# R7FA8M1AH register map
Vendor: Renesas; Series: RA8; File version: 1.2
CPU: CM85 r0p0, little endian, MPU, FPU, VTOR, 4 interrupt priority bits
Registers are 32-bit, read-write, reset 0x0 unless marked. A register's access mark holds for its fields unless they carry their own. Offsets are from the block's base; [hi:lo] are bit positions; {n}, {i} and the like mark numbered series; 'fields as' and 'values as' point back to an identical list.

## I3C (part 4 of 4) — I2C I3C unified IP
Base 0x4035F000
Same registers: I3C_NS 0x5035F000
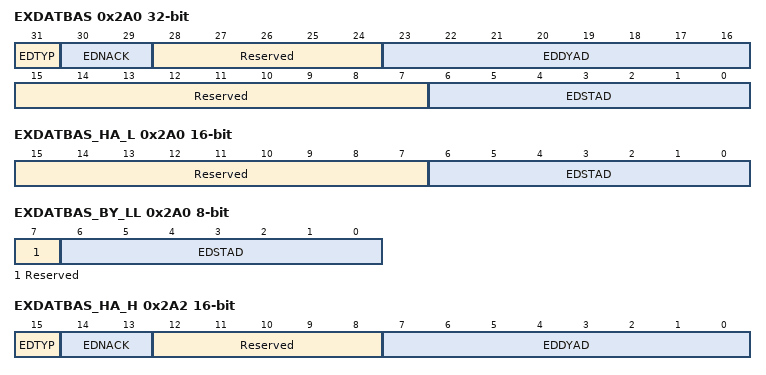
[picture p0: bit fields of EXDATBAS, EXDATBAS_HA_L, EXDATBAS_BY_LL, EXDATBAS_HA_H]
0x2A0 EXDATBAS — Extended Device Address Table Basic Register
  [31] EDTYP — Extended Device Type
    0=I3C: I3C Device; 1=I2C: I2C Device
  [30:29] EDNACK — Extended Device NACK Retry Count
  [28:24] Reserved — These bits are read as 00000. The write value should be 00000.
  [23:16] EDDYAD — Extended Device I3C Dynamic Address
  [15:7] Reserved — These bits are read as 000000000. The write value should be 000000000.
  [6:0] EDSTAD — Extended Device Static Address
0x2A0 EXDATBAS_HA_L 16-bit — Extended Device Address Table Basic Register
  [15:7] Reserved — These bits are read as 000000000. The write value should be 000000000.
  [6:0] EDSTAD — Extended Device Static Address
0x2A0 EXDATBAS_BY_LL 8-bit — Extended Device Address Table Basic Register
  [7] Reserved — This bit is read as 0. The write value should be 0.
  [6:0] EDSTAD — Extended Device Static Address
0x2A1 EXDATBAS_BY_LH 8-bit — Extended Device Address Table Basic Register
  [7:0] Reserved — These bits are read as 00000000. The write value should be 00000000.
0x2A2 EXDATBAS_HA_H 16-bit — Extended Device Address Table Basic Register
  [15] EDTYP — Extended Device Type
    0=I3C: I3C Device; 1=I2C: I2C Device
  [14:13] EDNACK — Extended Device NACK Retry Count
  [12:8] Reserved — These bits are read as 00000. The write value should be 00000.
  [7:0] EDDYAD — Extended Device I3C Dynamic Address
0x2A2 EXDATBAS_BY_HL 8-bit — Extended Device Address Table Basic Register
  [7:0] EDDYAD — Extended Device I3C Dynamic Address
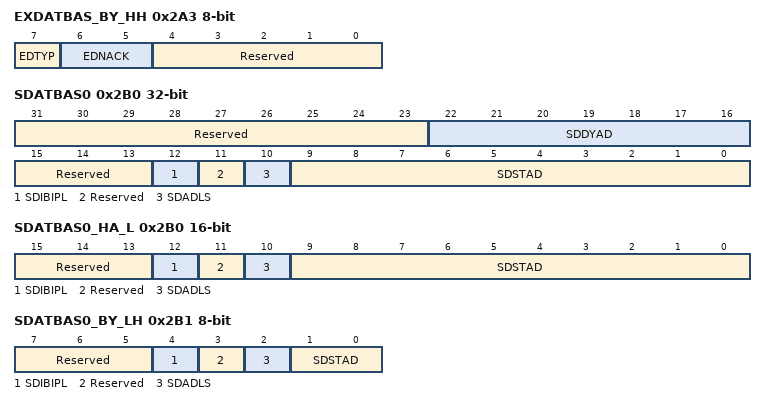
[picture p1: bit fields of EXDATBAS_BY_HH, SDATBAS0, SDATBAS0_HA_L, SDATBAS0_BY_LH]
0x2A3 EXDATBAS_BY_HH 8-bit — Extended Device Address Table Basic Register
  [7] EDTYP — Extended Device Type
    0=I3C: I3C Device; 1=I2C: I2C Device
  [6:5] EDNACK — Extended Device NACK Retry Count
  [4:0] Reserved — These bits are read as 00000. The write value should be 00000.
0x2B0 SDATBAS0 — Slave Device Address Table Basic Register 0
  [31:23] Reserved — These bits are read as 000000000. The write value should be 000000000.
  [22:16] SDDYAD read-modifies — Slave Device I3C Dynamic Address
  [15:13] Reserved — These bits are read as 000. The write value should be 000.
  [12] SDIBIPL ro — Slave Device IBI Payload
    0=IBIs from this Device do not carry a Data Payload; 1=IBIs from this Device do carry a Data Payload
  [11] Reserved — This bit is read as 0. The write value should be 0.
  [10] SDADLS — Slave Device Address Length Selection
    0=Slave Device address length 7 bits selected; 1=Slave Device address length 10 bits selected. (I2C device only)
  [9:0] SDSTAD — Slave Device Static Address
0x2B0 SDATBAS0_HA_L 16-bit — Slave Device Address Table Basic Register 0
  [15:13] Reserved — These bits are read as 000. The write value should be 000.
  [12] SDIBIPL ro — Slave Device IBI Payload
    values as SDATBAS0.SDIBIPL
  [11] Reserved — This bit is read as 0. The write value should be 0.
  [10] SDADLS — Slave Device Address Length Selection
    values as SDATBAS0.SDADLS
  [9:0] SDSTAD — Slave Device Static Address
{0x2B0+4i} SDATBAS{i}_BY_LL 8-bit (i=0..2) — Slave Device Address Table Basic Register {i}
  [7:0] SDSTAD — Slave Device Static Address
0x2B1 SDATBAS0_BY_LH 8-bit — Slave Device Address Table Basic Register 0
  [7:5] Reserved — These bits are read as 000. The write value should be 000.
  [4] SDIBIPL ro — Slave Device IBI Payload
    values as SDATBAS0.SDIBIPL
  [3] Reserved — This bit is read as 0. The write value should be 0.
  [2] SDADLS — Slave Device Address Length Selection
    values as SDATBAS0.SDADLS
  [1:0] SDSTAD — Slave Device Static Address
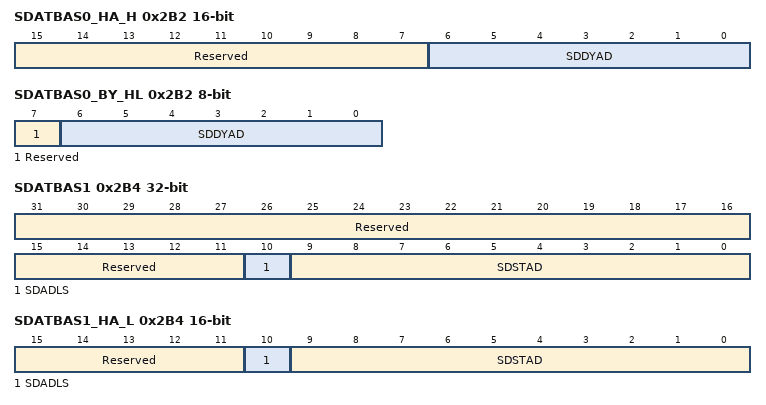
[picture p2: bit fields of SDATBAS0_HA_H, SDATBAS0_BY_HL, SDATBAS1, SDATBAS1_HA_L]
0x2B2 SDATBAS0_HA_H 16-bit — Slave Device Address Table Basic Register 0
  [15:7] Reserved — These bits are read as 000000000. The write value should be 000000000.
  [6:0] SDDYAD read-modifies — Slave Device I3C Dynamic Address
0x2B2 SDATBAS0_BY_HL 8-bit — Slave Device Address Table Basic Register 0
  [7] Reserved — This bit is read as 0. The write value should be 0.
  [6:0] SDDYAD read-modifies — Slave Device I3C Dynamic Address
0x2B4 SDATBAS1 — Slave Device Address Table Basic Register 1
  [31:11] Reserved — These bits are read as 000000000000000000000. The write value should be 000000000000000000000.
  [10] SDADLS — Slave Device Address Length Selection
    values as SDATBAS0.SDADLS
  [9:0] SDSTAD — Slave Device Static Address
0x2B4 SDATBAS1_HA_L 16-bit — Slave Device Address Table Basic Register 1
  [15:11] Reserved — These bits are read as 00000. The write value should be 00000.
  [10] SDADLS — Slave Device Address Length Selection
    values as SDATBAS0.SDADLS
  [9:0] SDSTAD — Slave Device Static Address
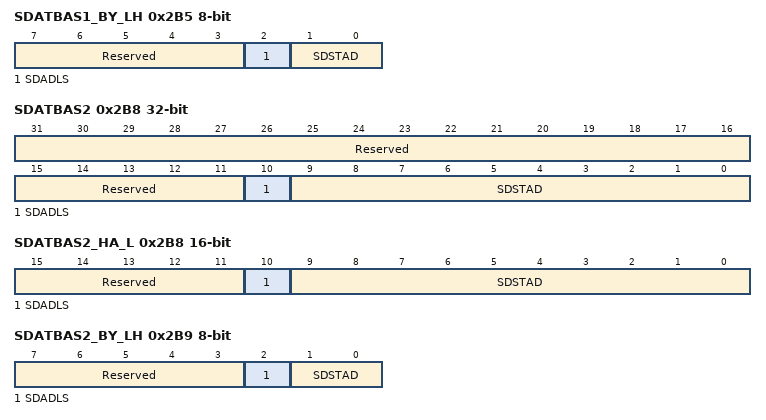
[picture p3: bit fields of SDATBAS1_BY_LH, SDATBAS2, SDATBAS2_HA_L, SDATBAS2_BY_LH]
0x2B5 SDATBAS1_BY_LH 8-bit — Slave Device Address Table Basic Register 1
  [7:3] Reserved — These bits are read as 00000. The write value should be 00000.
  [2] SDADLS — Slave Device Address Length Selection
    values as SDATBAS0.SDADLS
  [1:0] SDSTAD — Slave Device Static Address
0x2B8 SDATBAS2 — Slave Device Address Table Basic Register 2
  fields as SDATBAS1
0x2B8 SDATBAS2_HA_L 16-bit — Slave Device Address Table Basic Register 2
  fields as SDATBAS1_HA_L
0x2B9 SDATBAS2_BY_LH 8-bit — Slave Device Address Table Basic Register 2
  fields as SDATBAS1_BY_LH
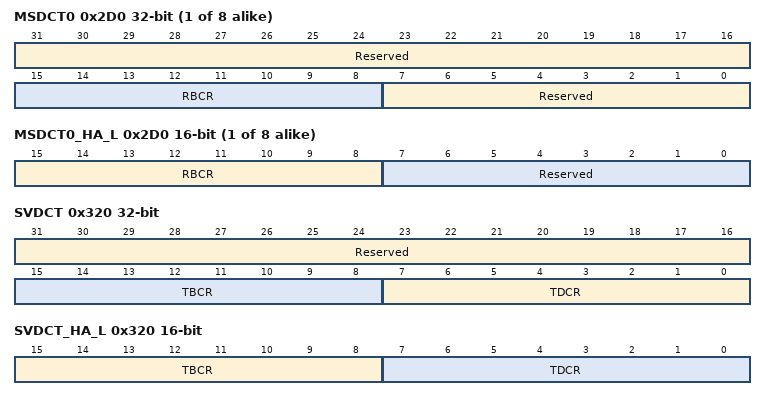
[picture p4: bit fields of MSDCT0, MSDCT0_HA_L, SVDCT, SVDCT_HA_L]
{0x2D0+4i} MSDCT{i} read-modifies (i=0..7) — Master Device Characteristic Table Register {i}
  [31:16] Reserved — These bits are read as 0000000000000000. The write value should be 0000000000000000.
  [15:8] RBCR read-modifies — Received Bus Characteristic RegisterValue of Device's I3C Bus Characteristics Register.
    0=– SDR only; 1=– HDR Capable; 0=– Not a Bridge Device; 1=– Is a Bridge Device; 0=– Device will always respond to I3C Bus commands; 1=– Device will not always respond to I3C Bus commands; 0=– No data byte follows the accepted IBI; 1=– Mandatory one or more data bytes follow the accepted IBI; 0=– Not Capable; 1=– Capable; 0=– No Limitation; 1=– Limitation
  [7:0] Reserved — These bits are read as 00000000. The write value should be 00000000.
{0x2D0+4i} MSDCT{i}_HA_L 16-bit read-modifies (i=0..7) — Master Device Characteristic Table Register {i}
  [15:8] RBCR read-modifies — Received Bus Characteristic RegisterValue of Device's I3C Bus Characteristics Register.
    values as MSDCT0.RBCR
  [7:0] Reserved — These bits are read as 00000000. The write value should be 00000000.
{0x2D1+4i} MSDCT{i}_BY_LH 8-bit read-modifies (i=0..7) — Master Device Characteristic Table Register {i}
  [7:0] RBCR read-modifies — Received Bus Characteristic RegisterValue of Device's I3C Bus Characteristics Register.
    values as MSDCT0.RBCR
0x320 SVDCT — Slave Device Characteristic Table Register
  [31:16] Reserved — These bits are read as 0000000000000000. The write value should be 0000000000000000.
  [15:8] TBCR — Transfar Bus Characteristic RegisterValue of Device's I3C Bus Characteristics Register.
    values as MSDCT0.RBCR
  [7:0] TDCR — Transfar Device Characteristic Register
0x320 SVDCT_HA_L 16-bit — Slave Device Characteristic Table Register
  [15:8] TBCR — Transfar Bus Characteristic RegisterValue of Device's I3C Bus Characteristics Register.
    values as MSDCT0.RBCR
  [7:0] TDCR — Transfar Device Characteristic Register
0x320 SVDCT_BY_LL 8-bit — Slave Device Characteristic Table Register
  [7:0] TDCR — Transfar Device Characteristic Register
0x321 SVDCT_BY_LH 8-bit — Slave Device Characteristic Table Register
  [7:0] TBCR — Transfar Bus Characteristic RegisterValue of Device's I3C Bus Characteristics Register.
    values as MSDCT0.RBCR
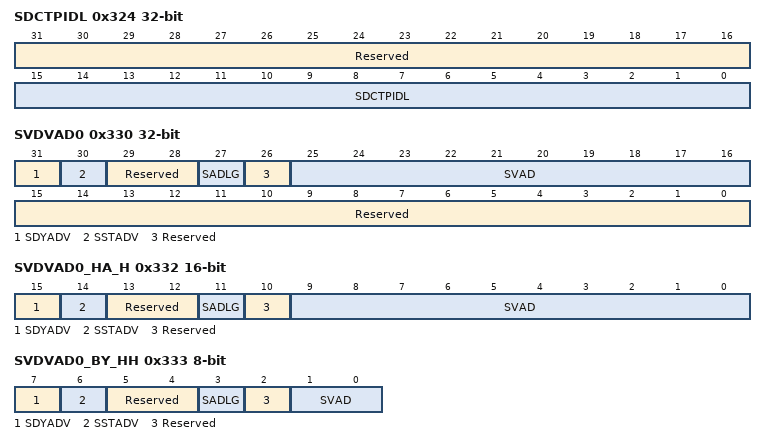
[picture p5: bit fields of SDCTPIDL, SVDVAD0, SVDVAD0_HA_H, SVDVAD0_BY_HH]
0x324 SDCTPIDL — Slave Device Characteristic Table Provisional ID Low Register
  [31:16] Reserved — These bits are read as 0000000000000000. The write value should be 0000000000000000.
  [15:0] SDCTPIDL — Transfar Device Provisional ID Low
0x324 SDCTPIDL_HA_L 16-bit — Slave Device Characteristic Table Provisional ID Low Register
  [15:0] SDCTPIDL — Transfar Device Provisional ID Low
0x324 SDCTPIDL_BY_LL 8-bit — Slave Device Characteristic Table Provisional ID Low Register
  [7:0] SDCTPIDL — Transfar Device Provisional ID Low
0x325 SDCTPIDL_BY_LH 8-bit — Slave Device Characteristic Table Provisional ID Low Register
  [7:0] SDCTPIDL — Transfar Device Provisional ID Low
0x328 SDCTPIDH — Slave Device Characteristic Table Provisional ID High Register
  [31:0] SDCTPIDH — Transfar Device Provisional ID High
0x328 SDCTPIDH_HA_L 16-bit — Slave Device Characteristic Table Provisional ID High Register
  [15:0] SDCTPIDH — Transfar Device Provisional ID High
0x328 SDCTPIDH_BY_LL 8-bit — Slave Device Characteristic Table Provisional ID High Register
  [7:0] SDCTPIDH — Transfar Device Provisional ID High
0x329 SDCTPIDH_BY_LH 8-bit — Slave Device Characteristic Table Provisional ID High Register
  [7:0] SDCTPIDH — Transfar Device Provisional ID High
0x32A SDCTPIDH_HA_H 16-bit — Slave Device Characteristic Table Provisional ID High Register
  [15:0] SDCTPIDH — Transfar Device Provisional ID High
0x32A SDCTPIDH_BY_HL 8-bit — Slave Device Characteristic Table Provisional ID High Register
  [7:0] SDCTPIDH — Transfar Device Provisional ID High
0x32B SDCTPIDH_BY_HH 8-bit — Slave Device Characteristic Table Provisional ID High Register
  [7:0] SDCTPIDH — Transfar Device Provisional ID High
0x330 SVDVAD0 ro — Slave Device Address Register 0
  [31] SDYADV — Slave Dynamic Address Valid
    0=Dynamic Address is disabled; 1=Dynamic Address is enabled
  [30] SSTADV — Slave Static Address Valid
    0=Slave address is disabled; 1=Slave address is enabled
  [29:28] Reserved — These bits are read as 00.
  [27] SADLG — Slave Address Length
    0=The 7-bit address format is selected; 1=The 10-bit address format is selected
  [26] Reserved — This bit is read as 0.
  [25:16] SVAD — Slave Address
  [15:0] Reserved — These bits are read as 0000000000000000.
0x332 SVDVAD0_HA_H 16-bit ro — Slave Device Address Register 0
  [15] SDYADV — Slave Dynamic Address Valid
    0=Dynamic Address is disabled; 1=Dynamic Address is enabled
  [14] SSTADV — Slave Static Address Valid
    0=Slave address is disabled; 1=Slave address is enabled
  [13:12] Reserved — These bits are read as 00.
  [11] SADLG — Slave Address Length
    values as SVDVAD0.SADLG
  [10] Reserved — This bit is read as 0.
  [9:0] SVAD — Slave Address
{0x332+4i} SVDVAD{i}_BY_HL 8-bit ro (i=0..2) — Slave Device Address Register {i}
  [7:0] SVAD — Slave Address
0x333 SVDVAD0_BY_HH 8-bit ro — Slave Device Address Register 0
  [7] SDYADV — Slave Dynamic Address Valid
    0=Dynamic Address is disabled; 1=Dynamic Address is enabled
  [6] SSTADV — Slave Static Address Valid
    0=Slave address is disabled; 1=Slave address is enabled
  [5:4] Reserved — These bits are read as 00.
  [3] SADLG — Slave Address Length
    values as SVDVAD0.SADLG
  [2] Reserved — This bit is read as 0.
  [1:0] SVAD — Slave Address
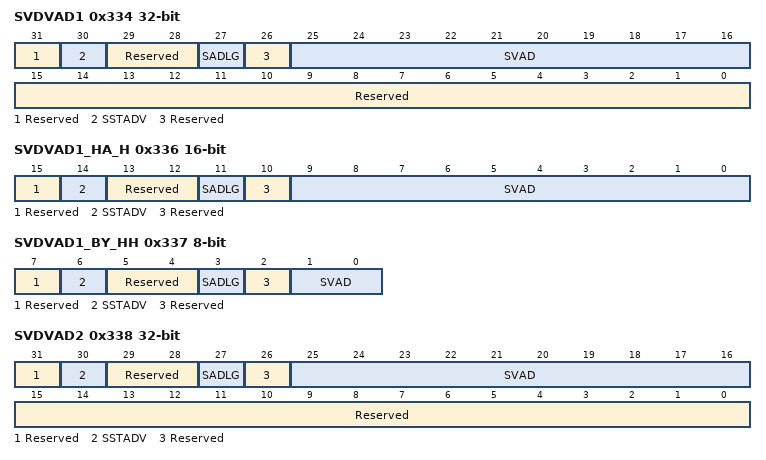
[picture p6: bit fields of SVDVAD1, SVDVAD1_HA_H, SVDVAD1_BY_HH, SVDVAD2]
0x334 SVDVAD1 ro — Slave Device Address Register 1
  [31] Reserved — This bit is read as 0.
  [30] SSTADV — Slave Static Address Valid
    0=Slave address is disabled; 1=Slave address is enabled
  [29:28] Reserved — These bits are read as 00.
  [27] SADLG — Slave Address Length
    values as SVDVAD0.SADLG
  [26] Reserved — This bit is read as 0.
  [25:16] SVAD — Slave Address
  [15:0] Reserved — These bits are read as 0000000000000000.
0x336 SVDVAD1_HA_H 16-bit ro — Slave Device Address Register 1
  [15] Reserved — This bit is read as 0.
  [14] SSTADV — Slave Static Address Valid
    0=Slave address is disabled; 1=Slave address is enabled
  [13:12] Reserved — These bits are read as 00.
  [11] SADLG — Slave Address Length
    values as SVDVAD0.SADLG
  [10] Reserved — This bit is read as 0.
  [9:0] SVAD — Slave Address
0x337 SVDVAD1_BY_HH 8-bit ro — Slave Device Address Register 1
  [7] Reserved — This bit is read as 0.
  [6] SSTADV — Slave Static Address Valid
    0=Slave address is disabled; 1=Slave address is enabled
  [5:4] Reserved — These bits are read as 00.
  [3] SADLG — Slave Address Length
    values as SVDVAD0.SADLG
  [2] Reserved — This bit is read as 0.
  [1:0] SVAD — Slave Address
0x338 SVDVAD2 ro — Slave Device Address Register 2
  fields as SVDVAD1
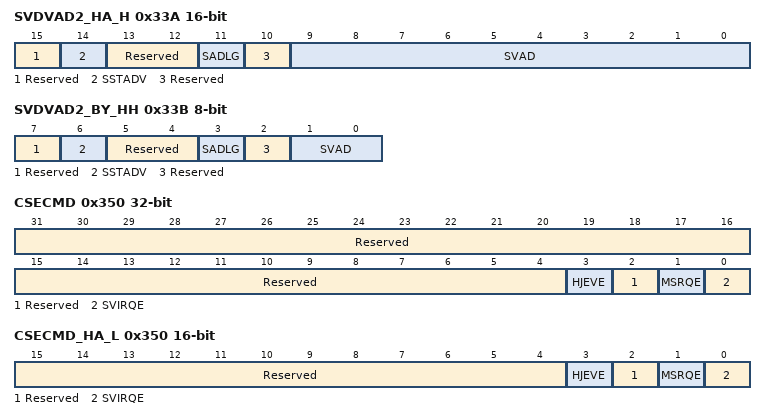
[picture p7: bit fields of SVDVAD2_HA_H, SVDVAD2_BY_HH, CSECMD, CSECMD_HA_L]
0x33A SVDVAD2_HA_H 16-bit ro — Slave Device Address Register 2
  fields as SVDVAD1_HA_H
0x33B SVDVAD2_BY_HH 8-bit ro — Slave Device Address Register 2
  fields as SVDVAD1_BY_HH
0x350 CSECMD read-modifies — CCC Slave Events Command Register
  [31:4] Reserved — These bits are read as 0000000000000000000000000000. The write value should be 0000000000000000000000000000.
  [3] HJEVE read-modifies — Hot-Join Event Enable
    0=DISABLED: Slave-initiated Hot-Join is Disabled by the Master to control; 1=ENABLED: Slave-initiated Hot-Join is Enabled by the Master to control
  [2] Reserved — This bit is read as 0. The write value should be 0.
  [1] MSRQE read-modifies — Mastership Requests Enable
    0=DISABLED: Mastership requests from Secondary Masters is Disabled by the Current Master to control; 1=ENABLED: Mastership requests from Secondary Masters is Enabled by the Current Master to control
  [0] SVIRQE read-modifies — Slave Interrupt Requests Enable
    0=DISABLED: Slave-initiated Interrupts is Disabled by the Master to control; 1=ENABLED: Slave-initiated Interrupts is Enabled by the Master to control
0x350 CSECMD_HA_L 16-bit read-modifies — CCC Slave Events Command Register
  [15:4] Reserved — These bits are read as 000000000000. The write value should be 000000000000.
  [3] HJEVE read-modifies — Hot-Join Event Enable
    values as CSECMD.HJEVE
  [2] Reserved — This bit is read as 0. The write value should be 0.
  [1] MSRQE read-modifies — Mastership Requests Enable
    values as CSECMD.MSRQE
  [0] SVIRQE read-modifies — Slave Interrupt Requests Enable
    values as CSECMD.SVIRQE
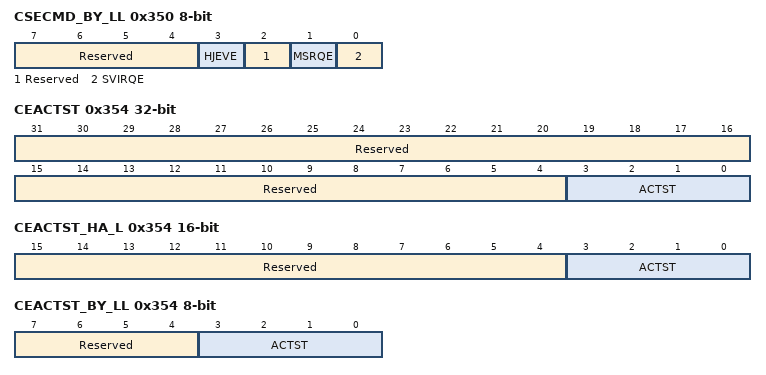
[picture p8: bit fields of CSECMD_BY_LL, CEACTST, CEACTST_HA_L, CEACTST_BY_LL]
0x350 CSECMD_BY_LL 8-bit read-modifies — CCC Slave Events Command Register
  [7:4] Reserved — These bits are read as 0000. The write value should be 0000.
  [3] HJEVE read-modifies — Hot-Join Event Enable
    values as CSECMD.HJEVE
  [2] Reserved — This bit is read as 0. The write value should be 0.
  [1] MSRQE read-modifies — Mastership Requests Enable
    values as CSECMD.MSRQE
  [0] SVIRQE read-modifies — Slave Interrupt Requests Enable
    values as CSECMD.SVIRQE
0x354 CEACTST read-modifies — CCC Enter Activity State Register
  [31:4] Reserved — These bits are read as 0000000000000000000000000000. The write value should be 0000000000000000000000000000.
  [3:0] ACTST read-modifies — Activity State
    1=ENTAS0 1μSec: Latency-free operation; 2=ENTAS1 100μSec; 4=ENTAS2 2mSec; 8=ENTAS3 50mSec: Lowest-activity operation
0x354 CEACTST_HA_L 16-bit read-modifies — CCC Enter Activity State Register
  [15:4] Reserved — These bits are read as 000000000000. The write value should be 000000000000.
  [3:0] ACTST read-modifies — Activity State
    values as CEACTST.ACTST
0x354 CEACTST_BY_LL 8-bit read-modifies — CCC Enter Activity State Register
  [7:4] Reserved — These bits are read as 0000. The write value should be 0000.
  [3:0] ACTST read-modifies — Activity State
    values as CEACTST.ACTST
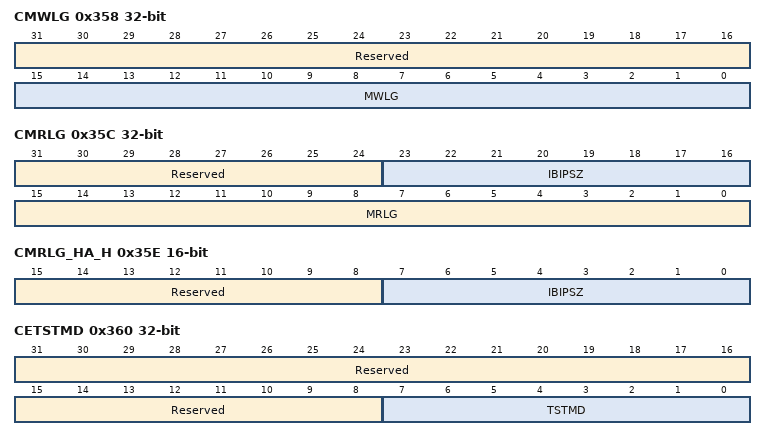
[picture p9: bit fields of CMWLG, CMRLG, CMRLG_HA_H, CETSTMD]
0x358 CMWLG read-modifies — CCC Max Write Length Register
  [31:16] Reserved — These bits are read as 0000000000000000. The write value should be 0000000000000000.
  [15:0] MWLG read-modifies — Max Write Length
0x358 CMWLG_HA_L 16-bit read-modifies — CCC Max Write Length Register
  [15:0] MWLG read-modifies — Max Write Length
0x358 CMWLG_BY_LL 8-bit read-modifies — CCC Max Write Length Register
  [7:0] MWLG read-modifies — Max Write Length
0x359 CMWLG_BY_LH 8-bit read-modifies — CCC Max Write Length Register
  [7:0] MWLG read-modifies — Max Write Length
0x35C CMRLG read-modifies — CCC Max Read Length Register
  [31:24] Reserved — These bits are read as 00000000. The write value should be 00000000.
  [23:16] IBIPSZ read-modifies — IBI Payload Size
  [15:0] MRLG read-modifies — Max Read Length.
0x35C CMRLG_HA_L 16-bit read-modifies — CCC Max Read Length Register
  [15:0] MRLG read-modifies — Max Read Length.
0x35C CMRLG_BY_LL 8-bit read-modifies — CCC Max Read Length Register
  [7:0] MRLG read-modifies — Max Read Length.
0x35D CMRLG_BY_LH 8-bit read-modifies — CCC Max Read Length Register
  [7:0] MRLG read-modifies — Max Read Length.
0x35E CMRLG_HA_H 16-bit read-modifies — CCC Max Read Length Register
  [15:8] Reserved — These bits are read as 00000000. The write value should be 00000000.
  [7:0] IBIPSZ read-modifies — IBI Payload Size
0x35E CMRLG_BY_HL 8-bit read-modifies — CCC Max Read Length Register
  [7:0] IBIPSZ read-modifies — IBI Payload Size
0x360 CETSTMD ro — CCC Enter Test Mode Register
  [31:8] Reserved — These bits are read as 000000000000000000000000.
  [7:0] TSTMD — Test Mode
    0=Exit Test Mode; 0b=This value removes all I3C Devices from Test Mode; 1=Vendor Test Mode; 0b=This value indicates that I3C Devices shall return a random 32bit value in the Provisional ID during the Dynamic Address Assignment procedure; 2=– 0xFF : MIPI Reserved; 0b=Reserved for future use by the MIPI Alliance
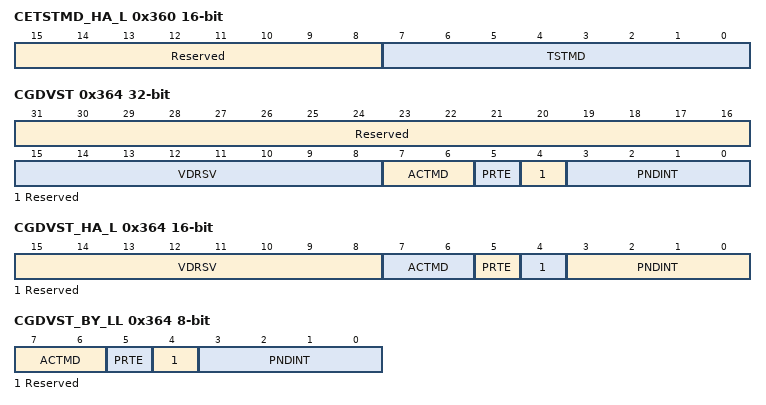
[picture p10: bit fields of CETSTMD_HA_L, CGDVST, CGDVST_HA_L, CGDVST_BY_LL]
0x360 CETSTMD_HA_L 16-bit ro — CCC Enter Test Mode Register
  [15:8] Reserved — These bits are read as 00000000.
  [7:0] TSTMD — Test Mode
    values as CETSTMD.TSTMD
0x360 CETSTMD_BY_LL 8-bit ro — CCC Enter Test Mode Register
  [7:0] TSTMD — Test Mode
    values as CETSTMD.TSTMD
0x364 CGDVST — CCC Get Device Status Register
  [31:16] Reserved — These bits are read as 0000000000000000. The write value should be 0000000000000000.
  [15:8] VDRSV — Vendor Reserved
  [7:6] ACTMD — Slave Device's current Activity Mode
    {v}=Activity Mode {v} (v=0..3)
  [5] PRTE ro — Protocol Error
    0=The Slave has not detected a protocol error since the last Status read; 1=The Slave has detected a protocol error since the last Status read
  [4] Reserved — This bit is read as 0. The write value should be 0.
  [3:0] PNDINT — Pending Interrupt
0x364 CGDVST_HA_L 16-bit — CCC Get Device Status Register
  [15:8] VDRSV — Vendor Reserved
  [7:6] ACTMD — Slave Device's current Activity Mode
    {v}=Activity Mode {v} (v=0..3)
  [5] PRTE ro — Protocol Error
    values as CGDVST.PRTE
  [4] Reserved — This bit is read as 0. The write value should be 0.
  [3:0] PNDINT — Pending Interrupt
0x364 CGDVST_BY_LL 8-bit — CCC Get Device Status Register
  [7:6] ACTMD — Slave Device's current Activity Mode
    {v}=Activity Mode {v} (v=0..3)
  [5] PRTE ro — Protocol Error
    values as CGDVST.PRTE
  [4] Reserved — This bit is read as 0. The write value should be 0.
  [3:0] PNDINT — Pending Interrupt
0x365 CGDVST_BY_LH 8-bit — CCC Get Device Status Register
  [7:0] VDRSV — Vendor Reserved
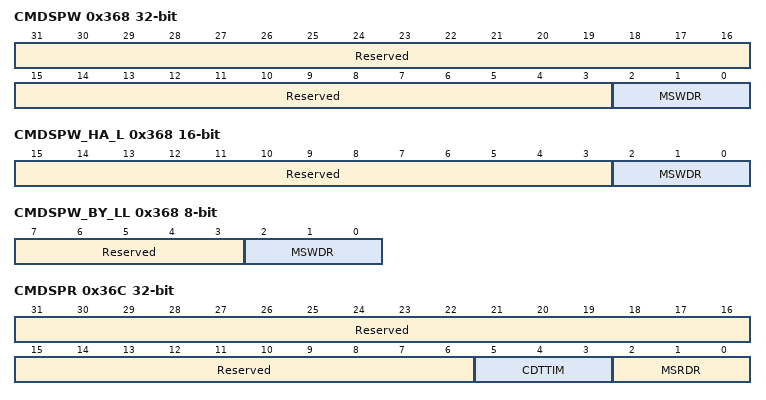
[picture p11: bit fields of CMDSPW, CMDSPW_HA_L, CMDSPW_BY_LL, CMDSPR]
0x368 CMDSPW — CCC Max Data Speed W(Write) Registe
  [31:3] Reserved — These bits are read as 00000000000000000000000000000. The write value should be 00000000000000000000000000000.
  [2:0] MSWDR — Maximum Sustained Write Data Rate
    0=fscl Max (default value); 1=8MHz
0x368 CMDSPW_HA_L 16-bit — CCC Max Data Speed W(Write) Registe
  [15:3] Reserved — These bits are read as 0000000000000. The write value should be 0000000000000.
  [2:0] MSWDR — Maximum Sustained Write Data Rate
    0=fscl Max (default value); 1=8MHz
0x368 CMDSPW_BY_LL 8-bit — CCC Max Data Speed W(Write) Registe
  [7:3] Reserved — These bits are read as 00000. The write value should be 00000.
  [2:0] MSWDR — Maximum Sustained Write Data Rate
    0=fscl Max (default value); 1=8MHz
0x36C CMDSPR — CCC Max Data Speed R(Read) Registe
  [31:6] Reserved — These bits are read as 00000000000000000000000000. The write value should be 00000000000000000000000000.
  [5:3] CDTTIM — Clock to Data Turnaround Time (TSCO)
    0=<= 8ns(default value); 1=<= 9ns
  [2:0] MSRDR — Maximum Sustained Read Data Rate
    0=fscl Max (default value); 1=8MHz
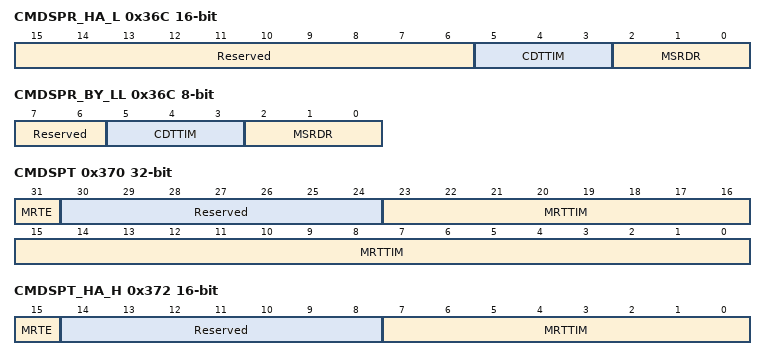
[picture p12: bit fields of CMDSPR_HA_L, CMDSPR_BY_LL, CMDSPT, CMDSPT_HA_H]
0x36C CMDSPR_HA_L 16-bit — CCC Max Data Speed R(Read) Registe
  [15:6] Reserved — These bits are read as 0000000000. The write value should be 0000000000.
  [5:3] CDTTIM — Clock to Data Turnaround Time (TSCO)
    0=<= 8ns(default value); 1=<= 9ns
  [2:0] MSRDR — Maximum Sustained Read Data Rate
    0=fscl Max (default value); 1=8MHz
0x36C CMDSPR_BY_LL 8-bit — CCC Max Data Speed R(Read) Registe
  [7:6] Reserved — These bits are read as 00. The write value should be 00.
  [5:3] CDTTIM — Clock to Data Turnaround Time (TSCO)
    0=<= 8ns(default value); 1=<= 9ns
  [2:0] MSRDR — Maximum Sustained Read Data Rate
    0=fscl Max (default value); 1=8MHz
0x370 CMDSPT — CCC Max Data Speed T(Turnaround) Registe
  [31] MRTE — Maximum Read Turnaround Time Enable
    0=Disables transmission of the Maximum Read Turnaround Time; 0b=(GETMXDS Format 1: Without Turnaround); 1=Enables transmission of the Maximum Read Turnaround Time; 0b=(GETMXDS Format 2: With Turnaround)
  [30:24] Reserved — These bits are read as 0000000. The write value should be 0000000.
  [23:0] MRTTIM — Maximum Read Turnaround Time24-bit field can encode turnaround times from 0.0 seconds to 16 seconds.
0x370 CMDSPT_HA_L 16-bit — CCC Max Data Speed T(Turnaround) Register
  [15:0] MRTTIM — Maximum Read Turnaround Time24-bit field can encode turnaround times from 0.0 seconds to 16 seconds.
0x370 CMDSPT_BY_LL 8-bit — CCC Max Data Speed T(Turnaround) Register
  [7:0] MRTTIM — Maximum Read Turnaround Time24-bit field can encode turnaround times from 0.0 seconds to 16 seconds.
0x371 CMDSPT_BY_LH 8-bit — CCC Max Data Speed T(Turnaround) Register
  fields as CMDSPT_BY_LL
0x372 CMDSPT_HA_H 16-bit — CCC Max Data Speed T(Turnaround) Register
  [15] MRTE — Maximum Read Turnaround Time Enable
    values as CMDSPT.MRTE
  [14:8] Reserved — These bits are read as 0000000. The write value should be 0000000.
  [7:0] MRTTIM — Maximum Read Turnaround Time24-bit field can encode turnaround times from 0.0 seconds to 16 seconds.
0x372 CMDSPT_BY_HL 8-bit — CCC Max Data Speed T(Turnaround) Register
  fields as CMDSPT_BY_LL
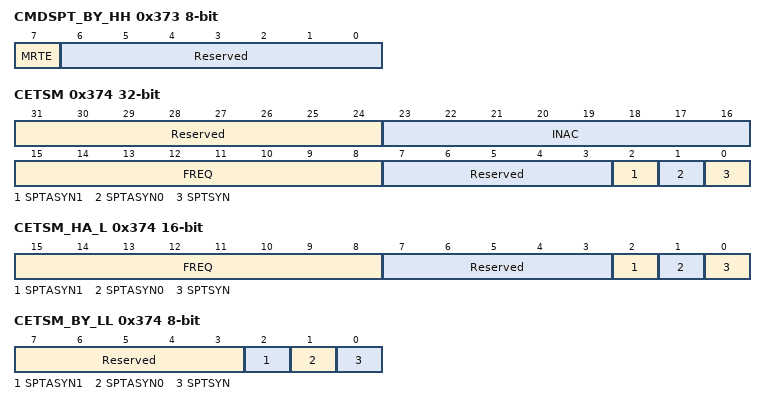
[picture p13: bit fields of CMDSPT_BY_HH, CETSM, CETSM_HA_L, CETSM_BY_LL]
0x373 CMDSPT_BY_HH 8-bit — CCC Max Data Speed T(Turnaround) Register
  [7] MRTE — Maximum Read Turnaround Time Enable
    values as CMDSPT.MRTE
  [6:0] Reserved — These bits are read as 0000000. The write value should be 0000000.
0x374 CETSM — CCC Exchange Timing Support Information M(Mode ) Register
  [31:24] Reserved — These bits are read as 00000000. The write value should be 00000000.
  [23:16] INAC — Inaccuracy ByteThis byte represents the maximum variation of the Slave's internal oscillator in 1/10th percent (0.1%) increments, up to 25.5%.
    0=0.0%; 15=1.5%; 31=3.1%; 47=4.7%; 63=6.3%; 79=7.9%; 95=9.5%; 111=11.1%; 127=12.7%; 143=14.3%; 159=15.9%; 175=17.5%; 191=19.1%; 207=20.7%; 223=22.3%; 239=23.9%; 255=25.5%
  [15:8] FREQ — Frequency ByteThis byte represents the Slave's internal oscillator frequency in increments of 0.5 MHz (500 kHz), up to 127.5 MHz.
    0=32.0KHz; 15=: 7.5MHz; 31=15.5MHz; 47=23.5MHz; 63=31.5MHz; 79=39.5MHz; 95=47.5MHz; 111=55.5MHz; 127=63.5MHz; 143=71.5MHz; 159=79.5MHz; 175=87.5MHz; 191=95.5MHz; 207=103.5MHz; 223=111.5MHz; 239=119.5MHz; 255=127.5MHz
  [7:3] Reserved — These bits are read as 00000. The write value should be 00000.
  [2] SPTASYN1 — Supports Async Mode 1
    0=Async Mode 1 is not supported; 1=Async Mode 1 is supported
  [1] SPTASYN0 — Supports Async Mode 0
    0=Async Mode 0 is not supported; 1=Async Mode 0 is supported
  [0] SPTSYN — Supports Sync Mode
    0=Disable Supports Sync Mode; 1=Enable Supports Sync Mode
0x374 CETSM_HA_L 16-bit — CCC Exchange Timing Support Information M(Mode ) Register
  [15:8] FREQ — Frequency ByteThis byte represents the Slave's internal oscillator frequency in increments of 0.5 MHz (500 kHz), up to 127.5 MHz.
    values as CETSM.FREQ
  [7:3] Reserved — These bits are read as 00000. The write value should be 00000.
  [2] SPTASYN1 — Supports Async Mode 1
    0=Async Mode 1 is not supported; 1=Async Mode 1 is supported
  [1] SPTASYN0 — Supports Async Mode 0
    0=Async Mode 0 is not supported; 1=Async Mode 0 is supported
  [0] SPTSYN — Supports Sync Mode
    0=Disable Supports Sync Mode; 1=Enable Supports Sync Mode
0x374 CETSM_BY_LL 8-bit — CCC Exchange Timing Support Information M(Mode ) Register
  [7:3] Reserved — These bits are read as 00000. The write value should be 00000.
  [2] SPTASYN1 — Supports Async Mode 1
    0=Async Mode 1 is not supported; 1=Async Mode 1 is supported
  [1] SPTASYN0 — Supports Async Mode 0
    0=Async Mode 0 is not supported; 1=Async Mode 0 is supported
  [0] SPTSYN — Supports Sync Mode
    0=Disable Supports Sync Mode; 1=Enable Supports Sync Mode
0x375 CETSM_BY_LH 8-bit — CCC Exchange Timing Support Information M(Mode ) Register
  [7:0] FREQ — Frequency ByteThis byte represents the Slave's internal oscillator frequency in increments of 0.5 MHz (500 kHz), up to 127.5 MHz.
    values as CETSM.FREQ
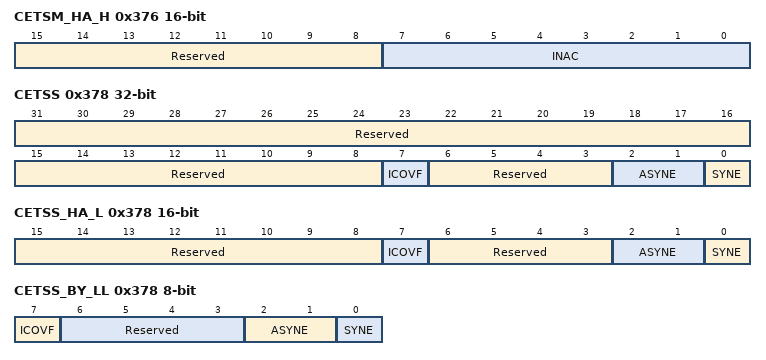
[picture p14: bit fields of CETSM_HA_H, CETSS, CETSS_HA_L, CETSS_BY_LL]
0x376 CETSM_HA_H 16-bit — CCC Exchange Timing Support Information M(Mode ) Register
  [15:8] Reserved — These bits are read as 00000000. The write value should be 00000000.
  [7:0] INAC — Inaccuracy ByteThis byte represents the maximum variation of the Slave's internal oscillator in 1/10th percent (0.1%) increments, up to 25.5%.
    values as CETSM.INAC
0x376 CETSM_BY_HL 8-bit — CCC Exchange Timing Support Information M(Mode ) Register
  [7:0] INAC — Inaccuracy ByteThis byte represents the maximum variation of the Slave's internal oscillator in 1/10th percent (0.1%) increments, up to 25.5%.
    values as CETSM.INAC
0x378 CETSS — CCC Exchange Timing Support Information S(State ) Register
  [31:8] Reserved — These bits are read as 000000000000000000000000. The write value should be 000000000000000000000000.
  [7] ICOVF read-modifies — Internal Counter Overflow
    0=Slave has not experienced a counter overflow since the most recent previous check; 1=Slave experienced a counter overflow since the most recent previous check
  [6:3] Reserved — These bits are read as 0000. The write value should be 0000.
  [2:1] ASYNE read-modifies — Async Mode Enabled
    0=All Mode Disable; 1=Async Mode 0 Enabled; 2=Async Mode 1 Enabled
  [0] SYNE — Sync Mode Enabled
    0=Sync Mode Disabled; 1=Sync Mode Enabled
0x378 CETSS_HA_L 16-bit — CCC Exchange Timing Support Information S(State ) Register
  [15:8] Reserved — These bits are read as 00000000. The write value should be 00000000.
  [7] ICOVF read-modifies — Internal Counter Overflow
    values as CETSS.ICOVF
  [6:3] Reserved — These bits are read as 0000. The write value should be 0000.
  [2:1] ASYNE read-modifies — Async Mode Enabled
    values as CETSS.ASYNE
  [0] SYNE — Sync Mode Enabled
    0=Sync Mode Disabled; 1=Sync Mode Enabled
0x378 CETSS_BY_LL 8-bit — CCC Exchange Timing Support Information S(State ) Register
  [7] ICOVF read-modifies — Internal Counter Overflow
    values as CETSS.ICOVF
  [6:3] Reserved — These bits are read as 0000. The write value should be 0000.
  [2:1] ASYNE read-modifies — Async Mode Enabled
    values as CETSS.ASYNE
  [0] SYNE — Sync Mode Enabled
    0=Sync Mode Disabled; 1=Sync Mode Enabled
0x37C CGHDRCAP — CCC Get HDR capability Register
  [31:3] Reserved — These bits are read as 00000000000000000000000000000. The write value should be 00000000000000000000000000000.
  [2] TSLEN — HDR-TSL Operation Enable
    0=HDR-TSL Operation is Disabled; 1=HDR-TSL Operation is Enabled
  [1] TSPEN — HDR-TSP Operation Enable
    0=HDR-TSP Operation is Disabled; 1=HDR-TSP Operation is Enabled
  [0] DDREN — HDR-DDR Operation Enable
    0=HDR-DDR Operation is Disabled; 1=HDR-DDR Operation is Enabled
0x37C CGHDRCAP_HA_L 16-bit — CCC Get HDR capability Register
  [15:3] Reserved — These bits are read as 0000000000000. The write value should be 0000000000000.
  [2] TSLEN — HDR-TSL Operation Enable
    values as CGHDRCAP.TSLEN
  [1] TSPEN — HDR-TSP Operation Enable
    values as CGHDRCAP.TSPEN
  [0] DDREN — HDR-DDR Operation Enable
    values as CGHDRCAP.DDREN
0x37C CGHDRCAP_BY_LL 8-bit — CCC Get HDR capability Register
  [7:3] Reserved — These bits are read as 00000. The write value should be 00000.
  [2] TSLEN — HDR-TSL Operation Enable
    values as CGHDRCAP.TSLEN
  [1] TSPEN — HDR-TSP Operation Enable
    values as CGHDRCAP.TSPEN
  [0] DDREN — HDR-DDR Operation Enable
    values as CGHDRCAP.DDREN
0x380 BITCNT ro — Bit Count Register
  [31:5] Reserved — These bits are read as 000000000000000000000000000.
  [4:0] BCNT — Bit Counter
0x380 BITCNT_HA_L 16-bit ro — Bit Count Register
  [15:5] Reserved — These bits are read as 00000000000.
  [4:0] BCNT — Bit Counter
0x380 BITCNT_BY_LL 8-bit ro — Bit Count Register
  [7:5] Reserved — These bits are read as 000.
  [4:0] BCNT — Bit Counter
0x394 NQSTLV ro reset 0x8 — Normal Queue Status Level Register
  [31:29] Reserved — These bits are read as 000.
  [28:24] IBISCNT — Normal IBI Status CountNumber of IBI Status entries currently in the IBI Queue.
  [23:16] IBIQLV — Normal IBI Queue Level Number of buffer entries currently in the IBI Queue.
  [15:8] RSPQLV — Normal Response Queue LevelNumber of buffer entries currently in the Response Queue.
  [7:0] CMDQFLV — Normal Command Queue Free LevelNumber of free buffer entries currently in the Command Queue. Reset value is the depth of the Command Queue.
0x394 NQSTLV_HA_L 16-bit ro reset 0x8 — Normal Queue Status Level Register
  [15:8] RSPQLV — Normal Response Queue LevelNumber of buffer entries currently in the Response Queue.
  [7:0] CMDQFLV — Normal Command Queue Free LevelNumber of free buffer entries currently in the Command Queue. Reset value is the depth of the Command Queue.
0x394 NQSTLV_BY_LL 8-bit ro reset 0x8 — Normal Queue Status Level Register
  [7:0] CMDQFLV — Normal Command Queue Free LevelNumber of free buffer entries currently in the Command Queue. Reset value is the depth of the Command Queue.
0x395 NQSTLV_BY_LH 8-bit ro — Normal Queue Status Level Register
  [7:0] RSPQLV — Normal Response Queue LevelNumber of buffer entries currently in the Response Queue.
0x396 NQSTLV_HA_H 16-bit ro — Normal Queue Status Level Register
  [15:13] Reserved — These bits are read as 000.
  [12:8] IBISCNT — Normal IBI Status CountNumber of IBI Status entries currently in the IBI Queue.
  [7:0] IBIQLV — Normal IBI Queue Level Number of buffer entries currently in the IBI Queue.
0x396 NQSTLV_BY_HL 8-bit ro — Normal Queue Status Level Register
  [7:0] IBIQLV — Normal IBI Queue Level Number of buffer entries currently in the IBI Queue.
0x397 NQSTLV_BY_HH 8-bit ro — Normal Queue Status Level Register
  [7:5] Reserved — These bits are read as 000.
  [4:0] IBISCNT — Normal IBI Status CountNumber of IBI Status entries currently in the IBI Queue.
0x398 NDBSTLV0 ro reset 0x1 — Normal Data Buffer Status Level Register 0
  [31:16] Reserved — These bits are read as 0000000000000000.
  [15:8] RDBLV — Normal Rx Data Buffer LevelIndicates the number of Rx Data Buffer entries in the Rx Data Queue.
  [7:0] TDBFLV — Normal Tx Data Buffer Free LevelIndicates the number of free Tx Data Buffer entries in the Tx Data Queue.Reset value is the depth of the Tx Data Queue.
0x398 NDBSTLV0_HA_L 16-bit ro reset 0x1 — Normal Data Buffer Status Level Register 0
  [15:8] RDBLV — Normal Rx Data Buffer LevelIndicates the number of Rx Data Buffer entries in the Rx Data Queue.
  [7:0] TDBFLV — Normal Tx Data Buffer Free LevelIndicates the number of free Tx Data Buffer entries in the Tx Data Queue.Reset value is the depth of the Tx Data Queue.
0x398 NDBSTLV0_BY_LL 8-bit ro reset 0x1 — Normal Data Buffer Status Level Register 0
  [7:0] TDBFLV — Normal Tx Data Buffer Free LevelIndicates the number of free Tx Data Buffer entries in the Tx Data Queue.Reset value is the depth of the Tx Data Queue.
0x399 NDBSTLV0_BY_LH 8-bit ro — Normal Data Buffer Status Level Register 0
  [7:0] RDBLV — Normal Rx Data Buffer LevelIndicates the number of Rx Data Buffer entries in the Rx Data Queue.
0x3C0 NRSQSTLV ro — Normal Receive Status Queue Status Level Register
  [31:8] Reserved — These bits are read as 000000000000000000000000.
  [7:0] RSQLV — Normal Receive Status Queue Level
0x3C0 NRSQSTLV_HA_L 16-bit ro — Normal Receive Status Queue Status Level Register
  [15:8] Reserved — These bits are read as 00000000.
  [7:0] RSQLV — Normal Receive Status Queue Level
0x3C0 NRSQSTLV_BY_LL 8-bit ro — Normal Receive Status Queue Status Level Register
  [7:0] RSQLV — Normal Receive Status Queue Level
0x3C4 HQSTLV ro reset 0x2 — High Priority Queue Status Level Register
  [31:16] Reserved — These bits are read as 0000000000000000.
  [15:8] RSPQLV — High Priority Response Queue LevelNumber of buffer entries currently in the High Priority Response Queue. Data Queue.
  [7:0] CMDQLV — High Priority Command Queue LevelNumber of free buffer entries currently in the High Priority Command Queue. Reset value is the depth of the High Priority Command Queue
0x3C4 HQSTLV_HA_L 16-bit ro reset 0x2 — High Priority Queue Status Level Register
  [15:8] RSPQLV — High Priority Response Queue LevelNumber of buffer entries currently in the High Priority Response Queue. Data Queue.
  [7:0] CMDQLV — High Priority Command Queue LevelNumber of free buffer entries currently in the High Priority Command Queue. Reset value is the depth of the High Priority Command Queue
0x3C4 HQSTLV_BY_LL 8-bit ro reset 0x2 — High Priority Queue Status Level Register
  [7:0] CMDQLV — High Priority Command Queue LevelNumber of free buffer entries currently in the High Priority Command Queue. Reset value is the depth of the High Priority Command Queue
0x3C5 HQSTLV_BY_LH 8-bit ro — High Priority Queue Status Level Register
  [7:0] RSPQLV — High Priority Response Queue LevelNumber of buffer entries currently in the High Priority Response Queue. Data Queue.
0x3C8 HDBSTLV ro reset 0x4 — High Priority Data Buffer Status Level Register
  [31:16] Reserved — These bits are read as 0000000000000000.
  [15:8] RDBLV — High Priority Rx Data Buffer Level Indicates the number of High Priority Rx Data Buffer entries in the High Priority Rx Data Queue.
  [7:0] TDBFLV — High Priority Tx Data Buffer Free LevelIndicates the number of free High Priority Tx Data Buffer entries in the High Priority Tx Data Queue.Reset value is the depth of the High Priority Tx Data Queue.
0x3C8 HDBSTLV_HA_L 16-bit ro reset 0x4 — High Priority Data Buffer Status Level Register
  [15:8] RDBLV — High Priority Rx Data Buffer Level Indicates the number of High Priority Rx Data Buffer entries in the High Priority Rx Data Queue.
  [7:0] TDBFLV — High Priority Tx Data Buffer Free LevelIndicates the number of free High Priority Tx Data Buffer entries in the High Priority Tx Data Queue.Reset value is the depth of the High Priority Tx Data Queue.
0x3C8 HDBSTLV_BY_LL 8-bit ro reset 0x4 — High Priority Data Buffer Status Level Register
  [7:0] TDBFLV — High Priority Tx Data Buffer Free LevelIndicates the number of free High Priority Tx Data Buffer entries in the High Priority Tx Data Queue.Reset value is the depth of the High Priority Tx Data Queue.
0x3C9 HDBSTLV_BY_LH 8-bit ro — High Priority Data Buffer Status Level Register
  [7:0] RDBLV — High Priority Rx Data Buffer Level Indicates the number of High Priority Rx Data Buffer entries in the High Priority Rx Data Queue.
0x3CC PRSTDBG ro reset 0xF — Present State Debug Register
  [31:28] Reserved — These bits are read as 0000.
  [27:24] Reserved — These bits are read as 0000.
  [23:22] Reserved — These bits are read as 00.
  [21:16] Reserved — These bits are read as 000000.
  [15:14] Reserved — These bits are read as 00.
  [13:8] Reserved — These bits are read as 000000.
  [7:4] Reserved — These bits are read as 0000.
  [3] SDOLV — SDA Output Level
    0=This IP has driven the SDA pin low; 1=This IP has released the SDA pin
  [2] SCOLV — SCL Output Level
    0=This IP has driven the SCL pin low; 1=This IP has released the SCL pin
  [1] SDILV — SDA Line Signal LevelThis bit is used to check the SDA Line level, in order to recover from errors and for debugging. This bit reflects the value of synchronized pt_sdai_a signal.
  [0] SCILV — SCL Line Signal LevelThis bit is used to check the SCL Line level, in order to recover from errors and for debugging. This bit reflects the value of synchronized pt_scli_a signal.
0x3CC PRSTDBG_HA_L 16-bit ro reset 0xF — Present State Debug Register
  [15:14] Reserved — These bits are read as 00.
  [13:8] Reserved — These bits are read as 000000.
  [7:4] Reserved — These bits are read as 0000.
  [3] SDOLV — SDA Output Level
    values as PRSTDBG.SDOLV
  [2] SCOLV — SCL Output Level
    values as PRSTDBG.SCOLV
  [1] SDILV — SDA Line Signal LevelThis bit is used to check the SDA Line level, in order to recover from errors and for debugging. This bit reflects the value of synchronized pt_sdai_a signal.
  [0] SCILV — SCL Line Signal LevelThis bit is used to check the SCL Line level, in order to recover from errors and for debugging. This bit reflects the value of synchronized pt_scli_a signal.
0x3CC PRSTDBG_BY_LL 8-bit ro reset 0xF — Present State Debug Register
  [7:4] Reserved — These bits are read as 0000.
  [3] SDOLV — SDA Output Level
    values as PRSTDBG.SDOLV
  [2] SCOLV — SCL Output Level
    values as PRSTDBG.SCOLV
  [1] SDILV — SDA Line Signal LevelThis bit is used to check the SDA Line level, in order to recover from errors and for debugging. This bit reflects the value of synchronized pt_sdai_a signal.
  [0] SCILV — SCL Line Signal LevelThis bit is used to check the SCL Line level, in order to recover from errors and for debugging. This bit reflects the value of synchronized pt_scli_a signal.
0x3CD PRSTDBG_BY_LH 8-bit ro — Present State Debug Register
  [7:6] Reserved — These bits are read as 00.
  [5:0] Reserved — These bits are read as 000000.
0x3CE PRSTDBG_HA_H 16-bit ro — Present State Debug Register
  [15:12] Reserved — These bits are read as 0000.
  [11:8] Reserved — These bits are read as 0000.
  [7:6] Reserved — These bits are read as 00.
  [5:0] Reserved — These bits are read as 000000.
0x3CE PRSTDBG_BY_HL 8-bit ro — Present State Debug Register
  fields as PRSTDBG_BY_LH
0x3CF PRSTDBG_BY_HH 8-bit ro — Present State Debug Register
  [7:4] Reserved — These bits are read as 0000.
  [3:0] Reserved — These bits are read as 0000.
0x3D0 MSERRCNT ro — Master Error Counters Register
  [31] Reserved — This bit is read as 0.
  [30:8] Reserved — These bits are read as 00000000000000000000000.
  [7:0] M2ECNT — M2 Error CounterCounts I3C Type M2 errors on the I3C Bus.Cleared upon Read out.
0x3D0 MSERRCNT_HA_L 16-bit ro — Master Error Counters Register
  [15:8] Reserved — These bits are read as 00000000.
  [7:0] M2ECNT — M2 Error CounterCounts I3C Type M2 errors on the I3C Bus.Cleared upon Read out.
0x3D0 MSERRCNT_BY_LL 8-bit ro — Master Error Counters Register
  [7:0] M2ECNT — M2 Error CounterCounts I3C Type M2 errors on the I3C Bus.Cleared upon Read out.
0x3E0 SC1CPT ro — SC1 Capture monitor Register
  [31:16] Reserved — These bits are read as 0000000000000000.
  [15:0] SC1C — SC1 Capture
0x3E0 SC1CPT_HA_L 16-bit ro — SC1 Capture monitor Register
  [15:0] SC1C — SC1 Capture
0x3E0 SC1CPT_BY_LL 8-bit ro — SC1 Capture monitor Register
  [7:0] SC1C — SC1 Capture
0x3E1 SC1CPT_BY_LH 8-bit ro — SC1 Capture monitor Register
  [7:0] SC1C — SC1 Capture
0x3E4 SC2CPT ro — SC2 Capture monitor Register
  [31:16] Reserved — These bits are read as 0000000000000000.
  [15:0] SC2C — SC2 Capture
0x3E4 SC2CPT_HA_L 16-bit ro — SC2 Capture monitor Register
  [15:0] SC2C — SC2 Capture
0x3E4 SC2CPT_BY_LL 8-bit ro — SC2 Capture monitor Register
  [7:0] SC2C — SC2 Capture
0x3E5 SC2CPT_BY_LH 8-bit ro — SC2 Capture monitor Register
  [7:0] SC2C — SC2 Capture
